# EMU_PRM register map
Vendor: Texas Instruments
Peripheral module from a debugger description file (folder omap4460).
Registers are 32-bit, access not given, reset 0x30000 unless marked. A register's access mark holds for its fields unless they carry their own. Offsets are as the file gives them; lines under a group give offsets from that group; [hi:lo] are bit positions; {n}, {i} and the like mark numbered series; 'fields as' and 'values as' point back to an identical list; <NAME> marks a mode.

## EMU_PRM
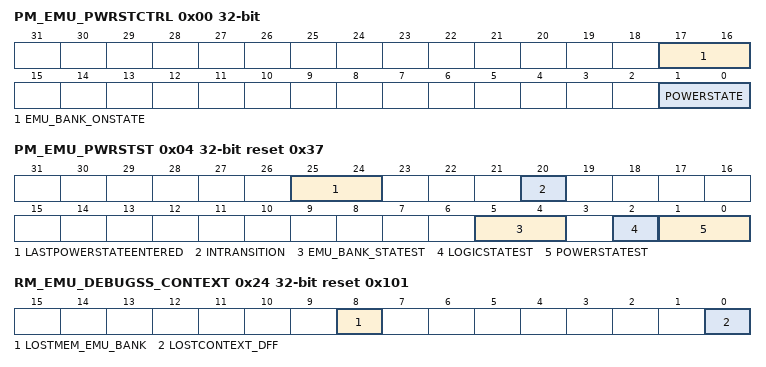
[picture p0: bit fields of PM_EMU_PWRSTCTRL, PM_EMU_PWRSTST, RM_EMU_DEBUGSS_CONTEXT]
0x00 PM_EMU_PWRSTCTRL — This register controls the EMU power state to reach upon a domain sleep transition
  [17:16] EMU_BANK_ONSTATE — EMU memory state when domain is ON. (access R Rreturns1s)
    3=EMU_BANK_ONSTATE_3_r (Memory bank is on when the domain is ON.)
  [1:0] POWERSTATE ro — Power state control
    0=POWERSTATE_0_r (OFF state)
0x04 PM_EMU_PWRSTST reset 0x37 — This register provides a status on the EMU domain current power state. [warm reset insensitive]
  [25:24] LASTPOWERSTATEENTERED — Last low power state entered. Set to 0x3 upon write of the same only. This register is intended for debug purpose only. (access RW W1toSet)
    0=LASTPOWERSTATEENTERED_0_r (Power domain was previously OFF); 1=LASTPOWERSTATEENTERED_1_r (Power domain was previously in RETENTION); 2=LASTPOWERSTATEENTERED_2_r (Power domain was previously ON-INACTIVE); 3=LASTPOWERSTATEENTERED_3_r (Power domain was previously ON-ACTIVE)
  [20] INTRANSITION ro — Domain transition status
    0=INTRANSITION_0_r (No ongoing transition on power domain); 1=INTRANSITION_1_r (Power domain transition is in progress.)
  [5:4] EMU_BANK_STATEST ro — EMU memory bank state status
    0=EMU_BANK_STATEST_0_r (Memory is OFF); 1=EMU_BANK_STATEST_1_r (Reserved); 2=EMU_BANK_STATEST_2_r (Reserved); 3=EMU_BANK_STATEST_3_r (Memory is ON It is supplied by WKUP LDO)
  [2] LOGICSTATEST ro — Logic state status
    0=LOGICSTATEST_0_r (Logic in domain is OFF); 1=LOGICSTATEST_1_r (Logic in domain is ON)
  [1:0] POWERSTATEST ro — Current power state status
    0=POWERSTATEST_0_r (Power domain is OFF); 3=POWERSTATEST_3_r (Power domain is ON-ACTIVE)
0x24 RM_EMU_DEBUGSS_CONTEXT reset 0x101 — This register contains dedicated DEBUGSS context statuses. [warm reset insensitive]
  [8] LOSTMEM_EMU_BANK — Specify if memory-based context in EMU_BANK memory bank has been lost due to a previous power transition or other reset source. (access RW W1toClr)
    0=Context has been maintained; 1=Context has been lost
  [0] LOSTCONTEXT_DFF — Specify if DFF-based context has been lost due to a previous power transition or other reset source. (set upon assertion of EMU_RST signal) (access RW W1toClr)
    0=Context has been maintained; 1=Context has been lost
